# MCU_CTRL_MMR_MCU_CTRL_MMR_CFG0_04500000h register map
Vendor: Texas Instruments
Peripheral module from a debugger description file (folder am62D).
Registers are 32-bit, read-write, reset 0x0 unless marked. A register's access mark holds for its fields unless they carry their own. Offsets are as the file gives them; lines under a group give offsets from that group; [hi:lo] are bit positions; {n}, {i} and the like mark numbered series; 'fields as' and 'values as' point back to an identical list; <NAME> marks a mode.

## MCU_CTRL_MMR_CFG0 (part 1 of 3)
0x8070 MCU_CTRL_MMR_CFG0_MCU_GPIO_CLKSEL
  [1:0] MCU_GPIO_CLKSEL_CLK_SEL — MCU_GPIO clock selection. Must be set to MCU_SYSCLK0/4 whenever MCU_GPIO VBUS interface is activated. Other clock source may be selected as a clk_sel up clock for DeepSleep modes after MCU_GPIO is gated off through LPSC.Field values (others are reserved):2'b00 - MCU_SYSCLK0 / 82'b01 - LFSOSC_CLKOUT 2'b10 - CLK_32K2'b11 - CLK_12M_RC Reset Source: mod_por_rst_n
0x8080 MCU_CTRL_MMR_CFG0_MCU_MCAN0_CLKSEL
  [1:0] MCU_MCAN0_CLKSEL_CLK_SEL — Selects the clock source for MCAN0Field values (others are reserved):2'b00 - MCU_PLL0_HSDIV4_CLKOUT2'b01 - MCU_EXT_REFCLK02'b10 - HFOSC0_CLKOUT2'b11 - HFOSC0_CLKOUT Reset Source: mod_g_rst_n
0x8084 MCU_CTRL_MMR_CFG0_MCU_MCAN1_CLKSEL
  [1:0] MCU_MCAN1_CLKSEL_CLK_SEL — Selects the clock source for MCAN1Field values (others are reserved):2'b00 - MCU_PLL0_HSDIV4_CLKOUT2'b01 - MCU_EXT_REFCLK02'b10 - HFOSC0_CLKOUT2'b11 - HFOSC0_CLKOUT Reset Source: mod_g_rst_n
0x80A0 MCU_CTRL_MMR_CFG0_MCU_SPI0_CLKSEL
  [16] MCU_SPI0_CLKSEL_MSTR_LB_CLKSEL — Controller mode receive capture clock loopback selection 1'b0 - Internal clock loopback 1'b1 - Loopback from pad Reset Source: mod_g_rst_n
0x80A4 MCU_CTRL_MMR_CFG0_MCU_SPI1_CLKSEL
  [16] MCU_SPI1_CLKSEL_MSTR_LB_CLKSEL — Controller mode receive capture clock loopback selection 1'b0 - Internal clock loopback 1'b1 - Loopback from pad Reset Source: mod_g_rst_n
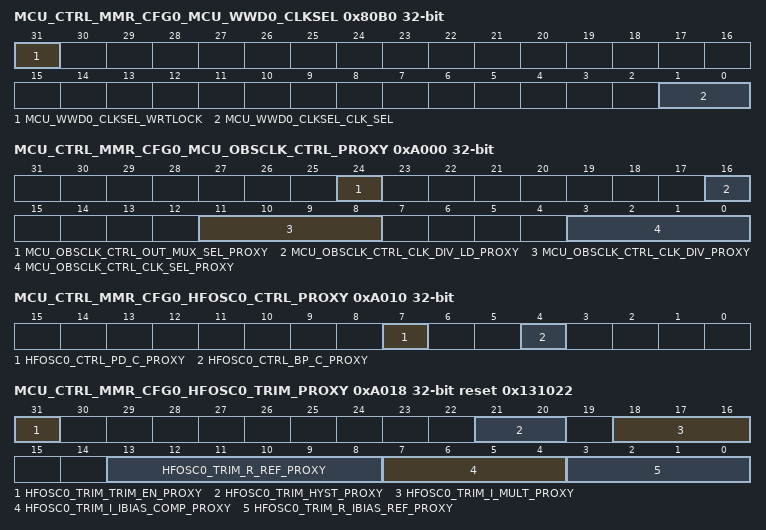
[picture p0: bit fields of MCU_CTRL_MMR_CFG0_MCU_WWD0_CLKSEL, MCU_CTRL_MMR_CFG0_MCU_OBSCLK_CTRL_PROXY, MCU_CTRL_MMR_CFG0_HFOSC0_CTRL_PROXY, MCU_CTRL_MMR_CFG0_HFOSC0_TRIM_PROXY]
0x80B0 MCU_CTRL_MMR_CFG0_MCU_WWD0_CLKSEL
  [31] MCU_WWD0_CLKSEL_WRTLOCK — When set, locks WWD0_CLKSEL from further writes until the next module reset. Reset Source: mod_g_rst_n
  [1:0] MCU_WWD0_CLKSEL_CLK_SEL — Windowed watchdog timer functional clock input select mux controlField values (others are reserved):2'b00 - HFOSC0_CLKOUT2'b01 - DEVICE_CLKOUT_32K2'b10 - CLK_12M_RC2'b11 - CLK_32K_RC Reset Source: mod_g_rst_n
0x9100 MCU_CTRL_MMR_CFG0_CLAIMREG_P2_R0_READONLY ro
  [31:0] CLAIMREG_P2_R0_READONLY — Claim bits for Partition 2 Reset Source: mod_g_rst_n
0x9104 MCU_CTRL_MMR_CFG0_CLAIMREG_P2_R1_READONLY ro
  [31:0] CLAIMREG_P2_R1_READONLY — Claim bits for Partition 2 Reset Source: mod_g_rst_n
0xA000 MCU_CTRL_MMR_CFG0_MCU_OBSCLK_CTRL_PROXY
  [24] MCU_OBSCLK_CTRL_OUT_MUX_SEL_PROXY — MCU_OBSCLK pin output mux selection.Note, HFOSC0_CLK is a direct output from the HFOSC0, distinct from HFOSC0_CLKOUT.Note, when HFOSC0_CLK is selected (1'b1) the MCU_OBSCLK_CTRL_clk_sel field must be programmed to 4'b0001. 1'b0 - The output of the MCU_OBSCLK output divider is output on the pin 1'b1 - HFOSC0_CLK is output on the pin Reset Source: mod_por_rst_n
  [16] MCU_OBSCLK_CTRL_CLK_DIV_LD_PROXY — Load the output divider valueWriting 1 to this bit will generate a load pulse to load the OBSCLK divider value. This bit can be cleared but must not be set in the same write cycle in which the clk_div value is changed. Reset Source: mod_por_rst_n
  [11:8] MCU_OBSCLK_CTRL_CLK_DIV_PROXY — MCU_OBSCLK pin clock selection output dividerOutput clock is divided by clk_div+1 Reset Source: mod_por_rst_n
  [3:0] MCU_OBSCLK_CTRL_CLK_SEL_PROXY — MCU_OBSCLK pin clock selectionField values (others are reserved):4'b0000 - CLK_12M_RC4'b0001 - '0'4'b0010 - MCU_PLL0_HSDIV0_CLKOUT4'b0011 - MCU_PLL0_HSDIV4_CLKOUT4'b0100 - MCU_PLLCTRL_OBSCLK4'b0101 - CLK_32K_RC4'b0110 - HFOSC0_CLKOUT4'b0111 - HFOSC0_CLKOUT_32K4'b1000 - MCU_SYSCLK04'b1001 - DEVICE_CLKOUT_32K Reset Source: mod_por_rst_n
0xA010 MCU_CTRL_MMR_CFG0_HFOSC0_CTRL_PROXY
  [7] HFOSC0_CTRL_PD_C_PROXY — Oscillator powerdown control. When set, oscillator is deactivated. Oscillator output is tristated if bp_c=0 Reset Source: mod_por_rst_n
  [4] HFOSC0_CTRL_BP_C_PROXY — Reserved - Must Write '0' Reset Source: mod_por_rst_n
0xA018 MCU_CTRL_MMR_CFG0_HFOSC0_TRIM_PROXY reset 0x131022
  [31] HFOSC0_TRIM_TRIM_EN_PROXY — Apply MMR values to OSC trim inputs instead of tie-offs Reset Source: mod_por_rst_n
  [21:20] HFOSC0_TRIM_HYST_PROXY — Sets comparator hysterisis Reset Source: mod_por_rst_n
  [18:16] HFOSC0_TRIM_I_MULT_PROXY — AGC AMP current multiplication gain Reset Source: mod_por_rst_n
  [13:8] HFOSC0_TRIM_R_REF_PROXY — Sets the AMP AGC bias current Reset Source: mod_por_rst_n
  [7:4] HFOSC0_TRIM_I_IBIAS_COMP_PROXY — Sets the COMP bias current Reset Source: mod_por_rst_n
  [3:0] HFOSC0_TRIM_R_IBIAS_REF_PROXY — Sets the base IBIAS reference Reset Source: mod_por_rst_n
0xA020 MCU_CTRL_MMR_CFG0_HFOSC0_STAT_PROXY ro
  [0] HFOSC0_STAT_DS_ON_WFI_STAT_PROXY — Allows MCU to monitor the DM attempting a Deep Sleep Reset Source: mod_g_rst_n
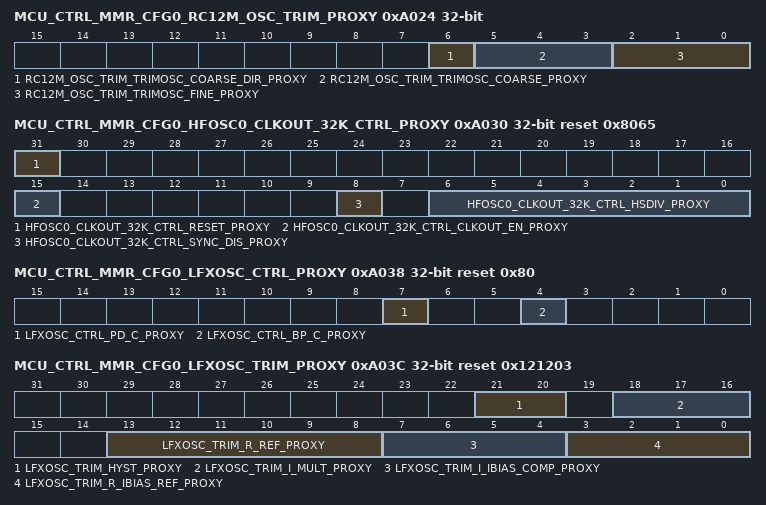
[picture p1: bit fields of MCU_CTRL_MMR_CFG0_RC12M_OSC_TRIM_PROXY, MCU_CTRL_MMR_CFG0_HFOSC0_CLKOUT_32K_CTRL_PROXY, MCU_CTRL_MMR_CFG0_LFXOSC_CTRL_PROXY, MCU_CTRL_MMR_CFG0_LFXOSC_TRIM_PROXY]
0xA024 MCU_CTRL_MMR_CFG0_RC12M_OSC_TRIM_PROXY
  [6] RC12M_OSC_TRIM_TRIMOSC_COARSE_DIR_PROXY — Coarse adjustment direction. If output is greater than 12.5 0 - Coarse adjustment decreases frequency 1 - Coarse adjustment increases frequency Reset Source: mod_por_rst_n
  [5:3] RC12M_OSC_TRIM_TRIMOSC_COARSE_PROXY — Coarse adjustment. Frequency is decreased or increased by 1.25 MHz per value based on the trimosc_coarse_dir value. Reset Source: mod_por_rst_n
  [2:0] RC12M_OSC_TRIM_TRIMOSC_FINE_PROXY — Fine adjustment. Decreases the frequency by 250 KHz per value. Reset Source: mod_por_rst_n
0xA030 MCU_CTRL_MMR_CFG0_HFOSC0_CLKOUT_32K_CTRL_PROXY reset 0x8065
  [31] HFOSC0_CLKOUT_32K_CTRL_RESET_PROXY — Asynchronous Divider Reset1 = Divider is Reset, HFOSC0_CLKOUT32K reset.0 = Divider out of reset, HFOSC0_CLKOUT_32K running. Reset Source: sys_por_rst_n
  [15] HFOSC0_CLKOUT_32K_CTRL_CLKOUT_EN_PROXY — HFOSC0_CLKOUT_32K activate: 0 = Synchronously Deactivate HFOSC0_CLKOUT_32KHz 1 = Synchronously Activate HFOSC0_CKLKOUT_32KHz Reset Source: sys_por_rst_n
  [8] HFOSC0_CLKOUT_32K_CTRL_SYNC_DIS_PROXY — HFOSC0_CLKOUT_32K Synchronize Deactivate 0 = Divider Updates are shadowed and take effect on counter reset. 1 = Divider Updates are immediate and hazardousDo not set this bit to 1'b1 during normal use. Reset Source: sys_por_rst_n
  [6:0] HFOSC0_CLKOUT_32K_CTRL_HSDIV_PROXY — HFOSC0_CLKOUT_32K divider:HFOSC0_CLKKOUT_32K Frequency = HFOSC0 Frequency / [8 * (hsdiv + 1)]Ex. HFOSC0 Frequency = 26MHz. hsdiv = 101 (Default)HFOSC0_CLKOUT_32K = 26MHz / (8 * (101+1)) = 26MHz / 816 = 31.9 KHz Reset Source: sys_por_rst_n
0xA038 MCU_CTRL_MMR_CFG0_LFXOSC_CTRL_PROXY reset 0x80
  [7] LFXOSC_CTRL_PD_C_PROXY — Oscillator powerdown control. When set, oscillator is deactivated. Oscillator output is tristated if bp_c=0 Reset Source: mod_por_rst_n
  [4] LFXOSC_CTRL_BP_C_PROXY — Oscillator bypass control. When set, oscillator is in bypass mode Reset Source: mod_por_rst_n
0xA03C MCU_CTRL_MMR_CFG0_LFXOSC_TRIM_PROXY reset 0x121203
  [21:20] LFXOSC_TRIM_HYST_PROXY — Sets comparator hysterisisField values (others are reserved):2'b00 - Hysteresis deactivated2'b01 - Type 1 hysteresis activated (Default)2'b10 - Type 2 hysteresis activated2'b11 - Both types 1 & 2 hysteresis activated Reset Source: mod_por_rst_n
  [18:16] LFXOSC_TRIM_I_MULT_PROXY — AGC AMP current multiplication gainField values (others are reserved):3'b000 - 3x AMP_AGC IBIAS3'b001 - 4x AMP_AGC IBIAS3'b010 - 5x AMP_AGC IBIAS (Default)3'b011 - 6x AMP_AGC IBIAS3'b100 - 7x AMP_AGC IBIAS3'b101 - 8x AMP_AGC IBIAS3'b110 - 9x AMP_AGC IBIAS3'b111 - 10x AMP_AGC IBIAS Reset Source: mod_por_rst_n
  [13:8] LFXOSC_TRIM_R_REF_PROXY — Sets the AMP AGC bias currentField values (others are reserved):6'b000000 - 0 K Ohm6'b000001 - 24 K Ohm6'b000010 - 48 K Ohm6'b000011 - 73 K Ohm6'b000100 - 97 K Ohm6'b000101 - 121 K Ohm6'b000110 - 145 K Ohm6'b000111 - 169 K Ohm6'b001000 - 193 K Ohm6'b001001 - 218 K Ohm6'b001010 - 242 K Ohm6'b001011 - 266 K Ohm6'b001100 - 290 K Ohm6'b001101 - 314 K Ohm6'b001110 - 338 K Ohm6'b001111 - 363 K Ohm6'b010000 - 387 K Ohm6'b010001 - 411 K Ohm6'b010010 - 435 K Ohm (Default)6'b010011 - 459 K Ohm6'b010100 - 483 K Ohm6'b010101 - 508 K Ohm6'b010110 - 532 K Ohm6'b010111 - 556 K Ohm6'b011000 - 580 K Ohm6'b011001 - 604 K Ohm6'b011010 - 628 K Ohm6'b011011 - 653 K Ohm6'b011100 - 677 K Ohm6'b011101 - 701 K Ohm6'b011110 - 725 K Ohm6'b011111 - 749 K Ohm6'b100000 - 773 K Ohm6'b100001 - 798 K Ohm6'b100010 - 822 K Ohm6'b100011 - 846 K Ohm6'b100100 - 870 K Ohm6'b100101 - 894 K Ohm6'b100110 - 918 K Ohm6'b100111 - 943 K Ohm6'b101000 - 967 K Ohm6'b101001 - 991 K Ohm6'b101010 - 1015 K Ohm6'b101011 - 1039 K Ohm6'b101100 - 1063 K Ohm6'b101101 - 1088 K Ohm6'b101110 - 1112 K Ohm6'b101111 - 1136 K Ohm6'b110000 - 1160 K Ohm6'b110001 - 1184 K Ohm6'b110010 - 1208 K Ohm6'b110011 - 1233 K Ohm6'b110100 - 1257 K Ohm6'b110101 - 1281 K Ohm6'b110110 - 1305 K Ohm6'b110111 - 1329 K Ohm6'b111000 - 1353 K Ohm6'b111001 - 1378 K Ohm6'b111010 - 1402 K Ohm6'b111011 - 1426 K Ohm6'b111100 - 1450 K Ohm6'b111101 - 1474 K Ohm6'b111110 - 1498 K Ohm6'b111111 - 1523 K Ohm Reset Source: mod_por_rst_n
  [7:4] LFXOSC_TRIM_I_IBIAS_COMP_PROXY — Sets the COMP bias currentField values (others are reserved):4'b0000 - Base IBIAS ref x24'b0001 - Base IBIAS ref x34'b0010 - Base IBIAS ref x44'b0011 - Base IBIAS ref x54'b0100 - Base IBIAS ref x64'b0101 - Base IBIAS ref x74'b0110 - Base IBIAS ref x84'b0111 - Base IBIAS ref x94'b1000 - Base IBIAS ref x104'b1001 - Base IBIAS ref x114'b1010 - Base IBIAS ref x124'b1011 - Base IBIAS ref x134'b1100 - Base IBIAS ref x144'b1101 - Base IBIAS ref x154'b1110 - Base IBIAS ref x164'b1111 - Base IBIAS ref x17 Reset Source: mod_por_rst_n
  [3:0] LFXOSC_TRIM_R_IBIAS_REF_PROXY — Sets the base IBIAS referenceField values (others are reserved):4'b0000 - 512 K Ohm4'b0001 - 576 K Ohm4'b0010 - 640 K Ohm4'b0011 - 704 K Ohm (Default)4'b0100 - 768 K Ohm4'b0101 - 832 K Ohm4'b0110 - 896 K Ohm4'b0111 - 960 K Ohm4'b1000 - 1024 K Ohm4'b1001 - 1088 K Ohm4'b1010 - 1152 K Ohm4'b1011 - 1216 K Ohm4'b1100 - 1280 K Ohm4'b1101 - 1344 K Ohm4'b1110 - 1408 K Ohm4'b1111 - 1472 K Ohm Reset Source: mod_por_rst_n
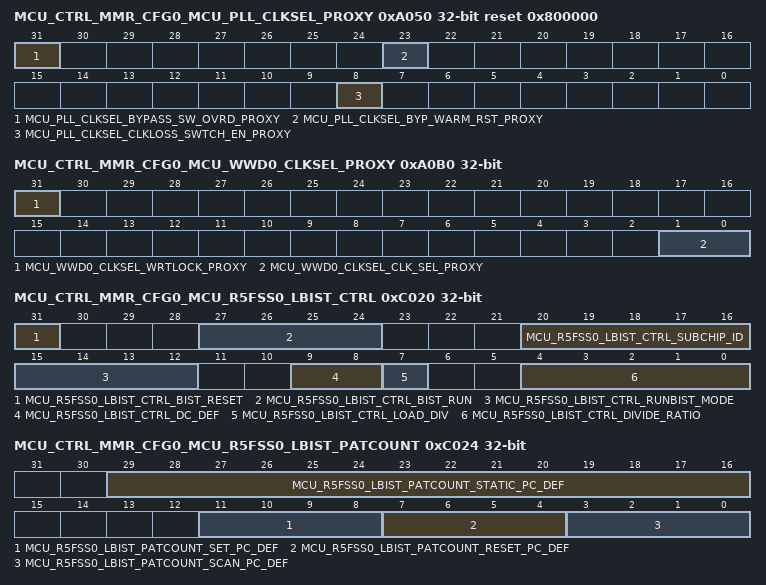
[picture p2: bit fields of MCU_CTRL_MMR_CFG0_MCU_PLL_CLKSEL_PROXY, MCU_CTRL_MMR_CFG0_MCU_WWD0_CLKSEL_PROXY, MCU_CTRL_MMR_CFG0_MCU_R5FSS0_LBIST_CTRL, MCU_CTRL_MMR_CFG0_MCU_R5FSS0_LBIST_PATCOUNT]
0xA050 MCU_CTRL_MMR_CFG0_MCU_PLL_CLKSEL_PROXY reset 0x800000
  [31] MCU_PLL_CLKSEL_BYPASS_SW_OVRD_PROXY — PLL Bypass warm reset software overrideWhen set, activates software control of exit from bypass mode on a mcu_reset_z for MCU PLL[2:0]. This bit must not be set until after the corresponding byp_warm_rst bit has been cleared or the PLL will immediately enter bypass mode. Reset Source: sys_por_rst_n
  [23] MCU_PLL_CLKSEL_BYP_WARM_RST_PROXY — PLL bypass mode after warm reset.This bit is only valid when bypass_sw_ovrd is set to 1'b1 to activate bypass software override.This bit is set (1'b1) when an MCU warm reset occurs and will keep MCU PLL[2:0] in bypass mode after reset exit until cleared by software. 1'b0 = Exit bypass mode (based on MCU PLL[2:0]_CTRL_bypass_en bit value) 1'b1 = Maintain bypass mode. Reset Source: mcu_chip1_rst_n
  [8] MCU_PLL_CLKSEL_CLKLOSS_SWTCH_EN_PROXY — When set, activates automatic switching of MCU PLL[2:0] clock source to CLK_12M_RC if HFOSC0 clock loss is detected Reset Source: mod_por_rst_n
0xA058 MCU_CTRL_MMR_CFG0_DEVICE_CLKOUT_32K_CTRL_PROXY
  [1:0] DEVICE_CLKOUT_32K_CTRL_CLK_32K_RC_SEL_PROXY — Selects the source of the device level 32KHz ClockField values (others are reserved):2'b00 - CLK_32K_RC2'b01 - HFOSC0_CLKOUT_32K2'b10 - Reserved - (implementation: CLK_32K_RC)2'b11 - LFOSC0_CLKOUT Reset Source: mod_g_rst_n
{0xA060+4i} MCU_CTRL_MMR_CFG0_MCU_TIMER{i}_CLKSEL_PROXY (i=0..3)
  [2:0] MCU_TIMER{i}_CLKSEL_CLK_SEL_PROXY — Timer functional clock input select mux control (Reserved values default to HFOSC0_CLK)Field values (others are reserved):3'b000 - HFOSC0_CLKOUT3'b001 - MCU_SYSCLK0 / 23'b010 - CLK_12M_RC3'b011 - MCU_PLL0_HSDIV5_CLKOUT3'b100 - MCU_EXT_REFCLK03'b101 - DEVICE_CLKOUT_32K3'b110 - CPSW_GENF03'b111 - CLK_32K_RC Reset Source: sys_por_rst_n
0xA070 MCU_CTRL_MMR_CFG0_MCU_GPIO_CLKSEL_PROXY
  [1:0] MCU_GPIO_CLKSEL_CLK_SEL_PROXY — MCU_GPIO clock selection. Must be set to MCU_SYSCLK0/4 whenever MCU_GPIO VBUS interface is activated. Other clock source may be selected as a clk_sel up clock for DeepSleep modes after MCU_GPIO is gated off through LPSC.Field values (others are reserved):2'b00 - MCU_SYSCLK0 / 82'b01 - LFSOSC_CLKOUT 2'b10 - CLK_32K2'b11 - CLK_12M_RC Reset Source: mod_por_rst_n
0xA080 MCU_CTRL_MMR_CFG0_MCU_MCAN0_CLKSEL_PROXY
  [1:0] MCU_MCAN0_CLKSEL_CLK_SEL_PROXY — Selects the clock source for MCAN0Field values (others are reserved):2'b00 - MCU_PLL0_HSDIV4_CLKOUT2'b01 - MCU_EXT_REFCLK02'b10 - HFOSC0_CLKOUT2'b11 - HFOSC0_CLKOUT Reset Source: mod_g_rst_n
0xA084 MCU_CTRL_MMR_CFG0_MCU_MCAN1_CLKSEL_PROXY
  [1:0] MCU_MCAN1_CLKSEL_CLK_SEL_PROXY — Selects the clock source for MCAN1Field values (others are reserved):2'b00 - MCU_PLL0_HSDIV4_CLKOUT2'b01 - MCU_EXT_REFCLK02'b10 - HFOSC0_CLKOUT2'b11 - HFOSC0_CLKOUT Reset Source: mod_g_rst_n
0xA0A0 MCU_CTRL_MMR_CFG0_MCU_SPI0_CLKSEL_PROXY
  [16] MCU_SPI0_CLKSEL_MSTR_LB_CLKSEL_PROXY — Controller mode receive capture clock loopback selection 1'b0 - Internal clock loopback 1'b1 - Loopback from pad Reset Source: mod_g_rst_n
0xA0A4 MCU_CTRL_MMR_CFG0_MCU_SPI1_CLKSEL_PROXY
  [16] MCU_SPI1_CLKSEL_MSTR_LB_CLKSEL_PROXY — Controller mode receive capture clock loopback selection 1'b0 - Internal clock loopback 1'b1 - Loopback from pad Reset Source: mod_g_rst_n
0xA0B0 MCU_CTRL_MMR_CFG0_MCU_WWD0_CLKSEL_PROXY
  [31] MCU_WWD0_CLKSEL_WRTLOCK_PROXY — When set, locks WWD0_CLKSEL from further writes until the next module reset. Reset Source: mod_g_rst_n
  [1:0] MCU_WWD0_CLKSEL_CLK_SEL_PROXY — Windowed watchdog timer functional clock input select mux controlField values (others are reserved):2'b00 - HFOSC0_CLKOUT2'b01 - DEVICE_CLKOUT_32K2'b10 - CLK_12M_RC2'b11 - CLK_32K_RC Reset Source: mod_g_rst_n
0xB100 MCU_CTRL_MMR_CFG0_CLAIMREG_P2_R0
  [31:0] CLAIMREG_P2_R0 — Claim bits for Partition 2 Reset Source: mod_g_rst_n
0xB104 MCU_CTRL_MMR_CFG0_CLAIMREG_P2_R1
  [31:0] CLAIMREG_P2_R1 — Claim bits for Partition 2 Reset Source: mod_g_rst_n
0xC020 MCU_CTRL_MMR_CFG0_MCU_R5FSS0_LBIST_CTRL
  [31] MCU_R5FSS0_LBIST_CTRL_BIST_RESET — This bitfield is not used. Reset Source: mod_g_rst_n
  [27:24] MCU_R5FSS0_LBIST_CTRL_BIST_RUN — This bitfield is not used. Reset Source: mod_g_rst_n
  [20:16] MCU_R5FSS0_LBIST_CTRL_SUBCHIP_ID — Specifies which sub-chip is to be tested Reset Source: mod_g_rst_n
  [15:12] MCU_R5FSS0_LBIST_CTRL_RUNBIST_MODE — Runbist mode activate if all bits are 1 Reset Source: mod_g_rst_n
  [9:8] MCU_R5FSS0_LBIST_CTRL_DC_DEF — Clock delay after scan_activate switching Reset Source: mod_g_rst_n
  [7] MCU_R5FSS0_LBIST_CTRL_LOAD_DIV — Loads LBIST clock divide ratio on transition from 0 to 1 Reset Source: mod_g_rst_n
  [4:0] MCU_R5FSS0_LBIST_CTRL_DIVIDE_RATIO — LBIST clock divide ratio Reset Source: mod_g_rst_n
0xC024 MCU_CTRL_MMR_CFG0_MCU_R5FSS0_LBIST_PATCOUNT
  [29:16] MCU_R5FSS0_LBIST_PATCOUNT_STATIC_PC_DEF — Number of stuck-at patterns to run Reset Source: mod_g_rst_n
  [11:8] MCU_R5FSS0_LBIST_PATCOUNT_SET_PC_DEF — Number of set patterns to run Reset Source: mod_g_rst_n
  [7:4] MCU_R5FSS0_LBIST_PATCOUNT_RESET_PC_DEF — Number of reset patterns to run Reset Source: mod_g_rst_n
  [3:0] MCU_R5FSS0_LBIST_PATCOUNT_SCAN_PC_DEF — Number of chain test patterns to run Reset Source: mod_g_rst_n
0xC028 MCU_CTRL_MMR_CFG0_MCU_R5FSS0_LBIST_SEED0
  [31:0] MCU_R5FSS0_LBIST_SEED0_PRPG_DEF — Initial seed for PRPG (bits 31:0) Reset Source: mod_g_rst_n
0xC02C MCU_CTRL_MMR_CFG0_MCU_R5FSS0_LBIST_SEED1
  [20:0] MCU_R5FSS0_LBIST_SEED1_PRPG_DEF — Initial seed for PRPG (bits 52:32) Reset Source: mod_g_rst_n
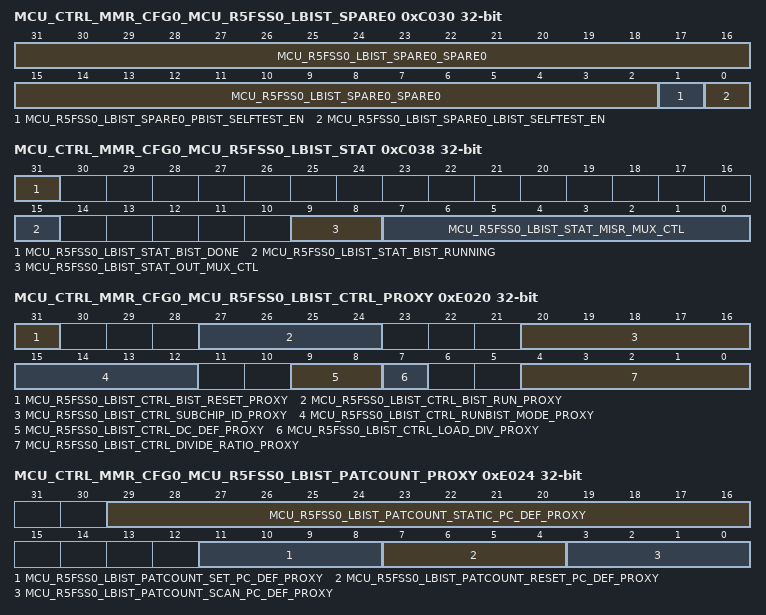
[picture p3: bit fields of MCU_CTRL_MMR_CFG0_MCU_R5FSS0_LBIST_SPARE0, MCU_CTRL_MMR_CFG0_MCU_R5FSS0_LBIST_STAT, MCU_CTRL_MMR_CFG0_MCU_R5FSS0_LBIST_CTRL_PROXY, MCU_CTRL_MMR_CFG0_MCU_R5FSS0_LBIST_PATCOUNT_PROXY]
0xC030 MCU_CTRL_MMR_CFG0_MCU_R5FSS0_LBIST_SPARE0
  [31:2] MCU_R5FSS0_LBIST_SPARE0_SPARE0 — LBIST spare bits Reset Source: mod_g_rst_n
  [1] MCU_R5FSS0_LBIST_SPARE0_PBIST_SELFTEST_EN — PBIST isolation control Reset Source: mod_g_rst_n
  [0] MCU_R5FSS0_LBIST_SPARE0_LBIST_SELFTEST_EN — LBIST isolation control Reset Source: mod_g_rst_n
0xC034 MCU_CTRL_MMR_CFG0_MCU_R5FSS0_LBIST_SPARE1
  [31:0] MCU_R5FSS0_LBIST_SPARE1_SPARE1 — LBIST spare bits Reset Source: mod_g_rst_n
0xC038 MCU_CTRL_MMR_CFG0_MCU_R5FSS0_LBIST_STAT access per field
  [31] MCU_R5FSS0_LBIST_STAT_BIST_DONE ro — LBIST is done Reset Source: mod_g_rst_n
  [15] MCU_R5FSS0_LBIST_STAT_BIST_RUNNING ro — LBIST is running Reset Source: mod_g_rst_n
  [9:8] MCU_R5FSS0_LBIST_STAT_OUT_MUX_CTL rw — Selects source of LBIST output 00 - LBIST IP PID value 01 - LBIST CTRL ID value 1x - MISR value Reset Source: mod_g_rst_n
  [7:0] MCU_R5FSS0_LBIST_STAT_MISR_MUX_CTL rw — Selects block of 32 MISR bits to read. A value of 0 selects a compacted 32-bit version of the full MISR. A value of 1-32 select a 32-bit segment of the MISR. Reset Source: mod_g_rst_n
0xC03C MCU_CTRL_MMR_CFG0_MCU_R5FSS0_LBIST_MISR ro
  [31:0] MCU_R5FSS0_LBIST_MISR_MISR_RESULT — 32-bits of MISR value selected by misr_mux_ctl Reset Source: mod_g_rst_n
0xD100 MCU_CTRL_MMR_CFG0_CLAIMREG_P3_R0_READONLY ro
  [31:0] CLAIMREG_P3_R0_READONLY — Claim bits for Partition 3 Reset Source: mod_g_rst_n
0xE020 MCU_CTRL_MMR_CFG0_MCU_R5FSS0_LBIST_CTRL_PROXY
  [31] MCU_R5FSS0_LBIST_CTRL_BIST_RESET_PROXY — This bitfield is not used. Reset Source: mod_g_rst_n
  [27:24] MCU_R5FSS0_LBIST_CTRL_BIST_RUN_PROXY — This bitfield is not used. Reset Source: mod_g_rst_n
  [20:16] MCU_R5FSS0_LBIST_CTRL_SUBCHIP_ID_PROXY — Specifies which sub-chip is to be tested Reset Source: mod_g_rst_n
  [15:12] MCU_R5FSS0_LBIST_CTRL_RUNBIST_MODE_PROXY — Runbist mode activate if all bits are 1 Reset Source: mod_g_rst_n
  [9:8] MCU_R5FSS0_LBIST_CTRL_DC_DEF_PROXY — Clock delay after scan_activate switching Reset Source: mod_g_rst_n
  [7] MCU_R5FSS0_LBIST_CTRL_LOAD_DIV_PROXY — Loads LBIST clock divide ratio on transition from 0 to 1 Reset Source: mod_g_rst_n
  [4:0] MCU_R5FSS0_LBIST_CTRL_DIVIDE_RATIO_PROXY — LBIST clock divide ratio Reset Source: mod_g_rst_n
0xE024 MCU_CTRL_MMR_CFG0_MCU_R5FSS0_LBIST_PATCOUNT_PROXY
  [29:16] MCU_R5FSS0_LBIST_PATCOUNT_STATIC_PC_DEF_PROXY — Number of stuck-at patterns to run Reset Source: mod_g_rst_n
  [11:8] MCU_R5FSS0_LBIST_PATCOUNT_SET_PC_DEF_PROXY — Number of set patterns to run Reset Source: mod_g_rst_n
  [7:4] MCU_R5FSS0_LBIST_PATCOUNT_RESET_PC_DEF_PROXY — Number of reset patterns to run Reset Source: mod_g_rst_n
  [3:0] MCU_R5FSS0_LBIST_PATCOUNT_SCAN_PC_DEF_PROXY — Number of chain test patterns to run Reset Source: mod_g_rst_n
0xE028 MCU_CTRL_MMR_CFG0_MCU_R5FSS0_LBIST_SEED0_PROXY
  [31:0] MCU_R5FSS0_LBIST_SEED0_PRPG_DEF_PROXY — Initial seed for PRPG (bits 31:0) Reset Source: mod_g_rst_n
0xE02C MCU_CTRL_MMR_CFG0_MCU_R5FSS0_LBIST_SEED1_PROXY
  [20:0] MCU_R5FSS0_LBIST_SEED1_PRPG_DEF_PROXY — Initial seed for PRPG (bits 52:32) Reset Source: mod_g_rst_n
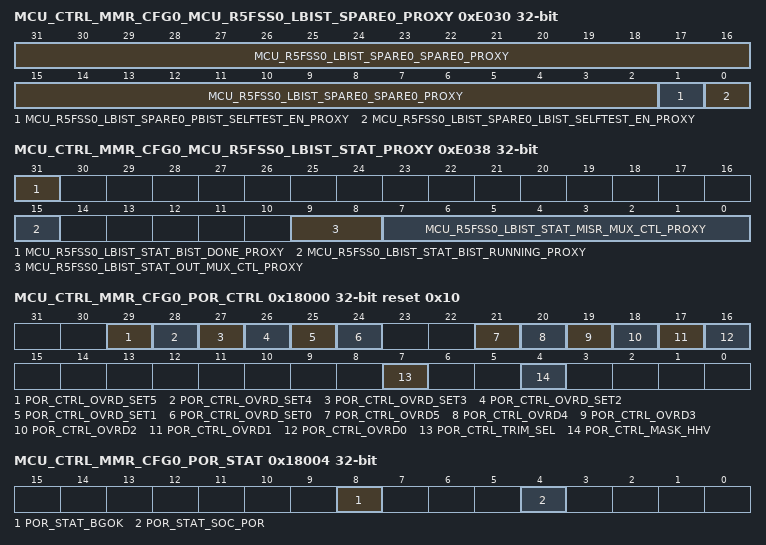
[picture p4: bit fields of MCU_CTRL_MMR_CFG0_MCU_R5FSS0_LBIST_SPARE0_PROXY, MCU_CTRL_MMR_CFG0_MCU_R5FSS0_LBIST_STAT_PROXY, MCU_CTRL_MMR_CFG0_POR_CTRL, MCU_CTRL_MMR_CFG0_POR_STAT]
0xE030 MCU_CTRL_MMR_CFG0_MCU_R5FSS0_LBIST_SPARE0_PROXY
  [31:2] MCU_R5FSS0_LBIST_SPARE0_SPARE0_PROXY — LBIST spare bits Reset Source: mod_g_rst_n
  [1] MCU_R5FSS0_LBIST_SPARE0_PBIST_SELFTEST_EN_PROXY — PBIST isolation control Reset Source: mod_g_rst_n
  [0] MCU_R5FSS0_LBIST_SPARE0_LBIST_SELFTEST_EN_PROXY — LBIST isolation control Reset Source: mod_g_rst_n
0xE034 MCU_CTRL_MMR_CFG0_MCU_R5FSS0_LBIST_SPARE1_PROXY
  [31:0] MCU_R5FSS0_LBIST_SPARE1_SPARE1_PROXY — LBIST spare bits Reset Source: mod_g_rst_n
0xE038 MCU_CTRL_MMR_CFG0_MCU_R5FSS0_LBIST_STAT_PROXY access per field
  [31] MCU_R5FSS0_LBIST_STAT_BIST_DONE_PROXY ro — LBIST is done Reset Source: mod_g_rst_n
  [15] MCU_R5FSS0_LBIST_STAT_BIST_RUNNING_PROXY ro — LBIST is running Reset Source: mod_g_rst_n
  [9:8] MCU_R5FSS0_LBIST_STAT_OUT_MUX_CTL_PROXY rw — Selects source of LBIST output 00 - LBIST IP PID value 01 - LBIST CTRL ID value 1x - MISR value Reset Source: mod_g_rst_n
  [7:0] MCU_R5FSS0_LBIST_STAT_MISR_MUX_CTL_PROXY rw — Selects block of 32 MISR bits to read. A value of 0 selects a compacted 32-bit version of the full MISR. A value of 1-32 select a 32-bit segment of the MISR. Reset Source: mod_g_rst_n
0xE03C MCU_CTRL_MMR_CFG0_MCU_R5FSS0_LBIST_MISR_PROXY ro
  [31:0] MCU_R5FSS0_LBIST_MISR_MISR_RESULT_PROXY — 32-bits of MISR value selected by misr_mux_ctl Reset Source: mod_g_rst_n
0xF100 MCU_CTRL_MMR_CFG0_CLAIMREG_P3_R0
  [31:0] CLAIMREG_P3_R0 — Claim bits for Partition 3 Reset Source: mod_g_rst_n
{0x11100+4i} MCU_CTRL_MMR_CFG0_CLAIMREG_P4_R{i}_READONLY ro (i=0..19)
  [31:0] CLAIMREG_P4_R{i}_READONLY — Claim bits for Partition 4 Reset Source: mod_g_rst_n
{0x13100+4i} MCU_CTRL_MMR_CFG0_CLAIMREG_P4_R{i} (i=0..19)
  [31:0] CLAIMREG_P4_R{i} — Claim bits for Partition 4 Reset Source: mod_g_rst_n
0x18000 MCU_CTRL_MMR_CFG0_POR_CTRL reset 0x10
  [29] POR_CTRL_OVRD_SET5 — Reserved override set Reset Source: mod_por_rst_n
  [28] POR_CTRL_OVRD_SET4 — POKLVB override set Reset Source: mod_por_rst_n
  [27] POR_CTRL_OVRD_SET3 — POKLVA override set Reset Source: mod_por_rst_n
  [26] POR_CTRL_OVRD_SET2 — POKHV override set Reset Source: mod_por_rst_n
  [25] POR_CTRL_OVRD_SET1 — BGOK override set Reset Source: mod_por_rst_n
  [24] POR_CTRL_OVRD_SET0 — PORHV override set Reset Source: mod_por_rst_n
  [21] POR_CTRL_OVRD5 — Reserved override activate Reset Source: mod_por_rst_n
  [20] POR_CTRL_OVRD4 — POKLVB override activate Reset Source: mod_por_rst_n
  [19] POR_CTRL_OVRD3 — POKLVA override activate Reset Source: mod_por_rst_n
  [18] POR_CTRL_OVRD2 — POKHV override activate Reset Source: mod_por_rst_n
  [17] POR_CTRL_OVRD1 — BGOK override activate Reset Source: mod_por_rst_n
  [16] POR_CTRL_OVRD0 — PORHV override activate Reset Source: mod_por_rst_n
  [7] POR_CTRL_TRIM_SEL — POR Trim Select 0 - Trim selections for Bandgap and POKs come from HHV defaults 1 - Trim selections for Bandgap and POKs come from POR_BANDGAP_CTRL and POR_POKxxx_CTRL registers Reset Source: mod_por_rst_n
  [4] POR_CTRL_MASK_HHV — Mask HHV/SOC_PORz outputs when applying new trim values Reset Source: mod_por_rst_n
0x18004 MCU_CTRL_MMR_CFG0_POR_STAT ro
  [8] POR_STAT_BGOK — Bandgap OK status Reset Source: mod_por_rst_n
  [4] POR_STAT_SOC_POR — POR module status 0 - Module is in functional mode 1 - Module is in reset mode Reset Source: mod_por_rst_n
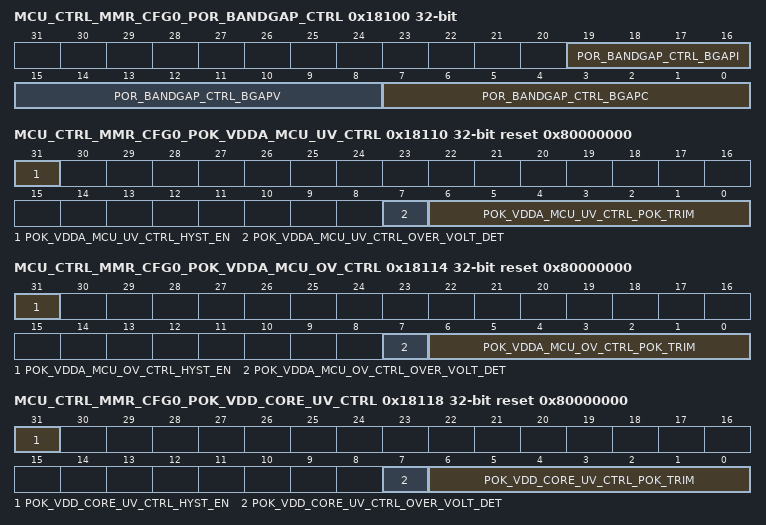
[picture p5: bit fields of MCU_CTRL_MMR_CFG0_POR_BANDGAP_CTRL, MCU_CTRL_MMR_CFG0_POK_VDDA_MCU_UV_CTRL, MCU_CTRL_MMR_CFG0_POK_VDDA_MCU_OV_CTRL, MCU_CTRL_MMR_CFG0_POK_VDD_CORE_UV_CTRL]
0x18100 MCU_CTRL_MMR_CFG0_POR_BANDGAP_CTRL
  [19:16] POR_BANDGAP_CTRL_BGAPI — Bandgap output current trim bits Reset Source: mod_por_rst_n
  [15:8] POR_BANDGAP_CTRL_BGAPV — Bandgap output voltage magnitude trim bits Reset Source: mod_por_rst_n
  [7:0] POR_BANDGAP_CTRL_BGAPC — Bandgap slope trim bits. Bit7 is used to calculate the offset Reset Source: mod_por_rst_n
0x18110 MCU_CTRL_MMR_CFG0_POK_VDDA_MCU_UV_CTRL reset 0x80000000
  [31] POK_VDDA_MCU_UV_CTRL_HYST_EN — Activate POK hysteresis Reset Source: mod_por_rst_n
  [7] POK_VDDA_MCU_UV_CTRL_OVER_VOLT_DET — Over / under voltage detection mode 0 - Under voltage detection 1 - Over voltage detection Reset Source: mod_por_rst_n
  [6:0] POK_VDDA_MCU_UV_CTRL_POK_TRIM — POK Trim Bits Reset Source: mod_por_rst_n
0x18114 MCU_CTRL_MMR_CFG0_POK_VDDA_MCU_OV_CTRL reset 0x80000000
  [31] POK_VDDA_MCU_OV_CTRL_HYST_EN — Activate POK hysteresis Reset Source: mod_por_rst_n
  [7] POK_VDDA_MCU_OV_CTRL_OVER_VOLT_DET — Over / under voltage detection mode 0 - Under voltage detection 1 - Over voltage detection Reset Source: mod_por_rst_n
  [6:0] POK_VDDA_MCU_OV_CTRL_POK_TRIM — POK Trim Bits Reset Source: mod_por_rst_n
0x18118 MCU_CTRL_MMR_CFG0_POK_VDD_CORE_UV_CTRL reset 0x80000000
  [31] POK_VDD_CORE_UV_CTRL_HYST_EN — Activate POK hysteresis Reset Source: mod_por_rst_n
  [7] POK_VDD_CORE_UV_CTRL_OVER_VOLT_DET — Over / under voltage detection mode 0 - Under voltage detection 1 - Over voltage detection Reset Source: mod_por_rst_n
  [6:0] POK_VDD_CORE_UV_CTRL_POK_TRIM — POK Trim Bits Reset Source: mod_por_rst_n
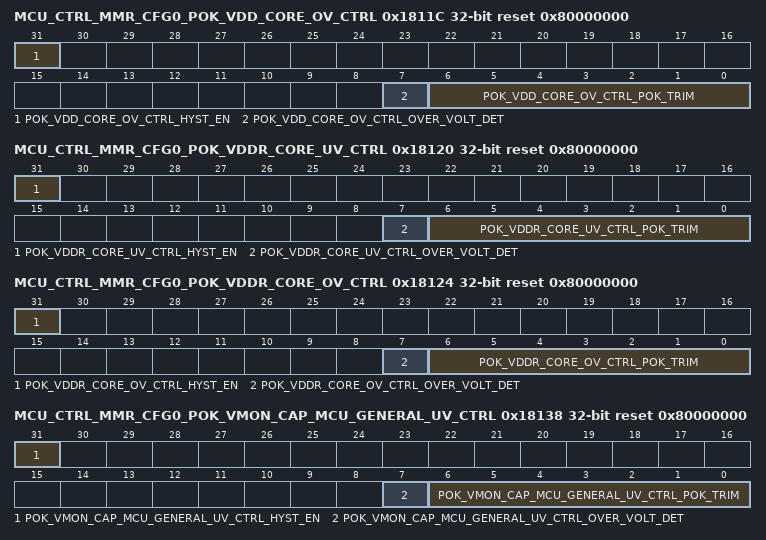
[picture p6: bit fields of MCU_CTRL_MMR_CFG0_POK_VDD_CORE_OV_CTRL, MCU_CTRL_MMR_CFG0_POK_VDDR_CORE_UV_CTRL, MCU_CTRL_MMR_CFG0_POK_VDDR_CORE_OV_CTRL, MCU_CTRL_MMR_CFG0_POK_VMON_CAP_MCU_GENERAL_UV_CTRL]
0x1811C MCU_CTRL_MMR_CFG0_POK_VDD_CORE_OV_CTRL reset 0x80000000
  [31] POK_VDD_CORE_OV_CTRL_HYST_EN — Activate POK hysteresis Reset Source: mod_por_rst_n
  [7] POK_VDD_CORE_OV_CTRL_OVER_VOLT_DET — Over / under voltage detection mode 0 - Under voltage detection 1 - Over voltage detection Reset Source: mod_por_rst_n
  [6:0] POK_VDD_CORE_OV_CTRL_POK_TRIM — POK Trim Bits Reset Source: mod_por_rst_n
0x18120 MCU_CTRL_MMR_CFG0_POK_VDDR_CORE_UV_CTRL reset 0x80000000
  [31] POK_VDDR_CORE_UV_CTRL_HYST_EN — Activate POK hysteresis Reset Source: mod_por_rst_n
  [7] POK_VDDR_CORE_UV_CTRL_OVER_VOLT_DET — Over / under voltage detection mode 0 - Under voltage detection 1 - Over voltage detection Reset Source: mod_por_rst_n
  [6:0] POK_VDDR_CORE_UV_CTRL_POK_TRIM — POK Trim Bits Reset Source: mod_por_rst_n
0x18124 MCU_CTRL_MMR_CFG0_POK_VDDR_CORE_OV_CTRL reset 0x80000000
  [31] POK_VDDR_CORE_OV_CTRL_HYST_EN — Activate POK hysteresis Reset Source: mod_por_rst_n
  [7] POK_VDDR_CORE_OV_CTRL_OVER_VOLT_DET — Over / under voltage detection mode 0 - Under voltage detection 1 - Over voltage detection Reset Source: mod_por_rst_n
  [6:0] POK_VDDR_CORE_OV_CTRL_POK_TRIM — POK Trim Bits Reset Source: mod_por_rst_n
0x18138 MCU_CTRL_MMR_CFG0_POK_VMON_CAP_MCU_GENERAL_UV_CTRL reset 0x80000000
  [31] POK_VMON_CAP_MCU_GENERAL_UV_CTRL_HYST_EN — Activate POK hysteresis Reset Source: mod_por_rst_n
  [7] POK_VMON_CAP_MCU_GENERAL_UV_CTRL_OVER_VOLT_DET — Over / under voltage detection mode 0 - Under voltage detection 1 - Over voltage detection Reset Source: mod_por_rst_n
  [6:0] POK_VMON_CAP_MCU_GENERAL_UV_CTRL_POK_TRIM — POK Trim Bits Reset Source: mod_por_rst_n
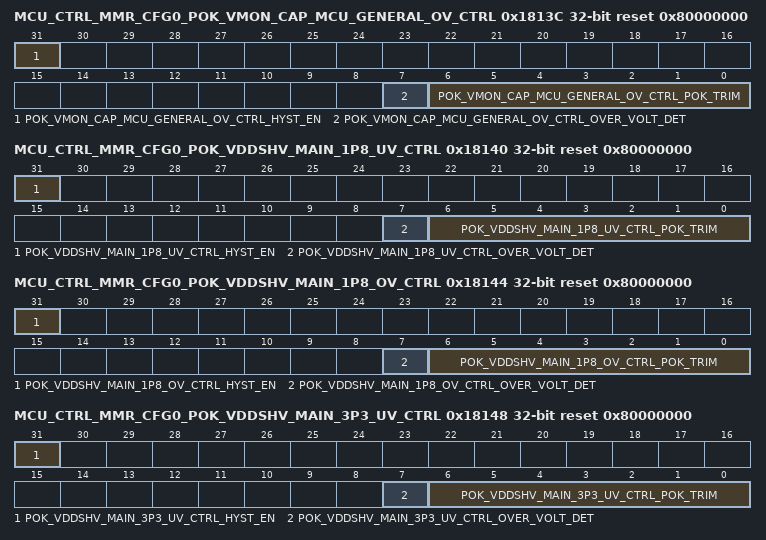
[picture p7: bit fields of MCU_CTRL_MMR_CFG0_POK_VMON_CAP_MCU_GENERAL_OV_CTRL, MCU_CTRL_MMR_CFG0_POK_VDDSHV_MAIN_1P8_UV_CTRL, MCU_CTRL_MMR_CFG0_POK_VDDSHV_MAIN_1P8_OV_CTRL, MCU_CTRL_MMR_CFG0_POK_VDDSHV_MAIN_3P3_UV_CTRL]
0x1813C MCU_CTRL_MMR_CFG0_POK_VMON_CAP_MCU_GENERAL_OV_CTRL reset 0x80000000
  [31] POK_VMON_CAP_MCU_GENERAL_OV_CTRL_HYST_EN — Activate POK hysteresis Reset Source: mod_por_rst_n
  [7] POK_VMON_CAP_MCU_GENERAL_OV_CTRL_OVER_VOLT_DET — Over / under voltage detection mode 0 - Under voltage detection 1 - Over voltage detection Reset Source: mod_por_rst_n
  [6:0] POK_VMON_CAP_MCU_GENERAL_OV_CTRL_POK_TRIM — POK Trim Bits Reset Source: mod_por_rst_n
0x18140 MCU_CTRL_MMR_CFG0_POK_VDDSHV_MAIN_1P8_UV_CTRL reset 0x80000000
  [31] POK_VDDSHV_MAIN_1P8_UV_CTRL_HYST_EN — Activate POK hysteresis Reset Source: mod_por_rst_n
  [7] POK_VDDSHV_MAIN_1P8_UV_CTRL_OVER_VOLT_DET — Over / under voltage detection mode 0 - Under voltage detection 1 - Over voltage detection Reset Source: mod_por_rst_n
  [6:0] POK_VDDSHV_MAIN_1P8_UV_CTRL_POK_TRIM — POK Trim Bits Reset Source: mod_por_rst_n
0x18144 MCU_CTRL_MMR_CFG0_POK_VDDSHV_MAIN_1P8_OV_CTRL reset 0x80000000
  [31] POK_VDDSHV_MAIN_1P8_OV_CTRL_HYST_EN — Activate POK hysteresis Reset Source: mod_por_rst_n
  [7] POK_VDDSHV_MAIN_1P8_OV_CTRL_OVER_VOLT_DET — Over / under voltage detection mode 0 - Under voltage detection 1 - Over voltage detection Reset Source: mod_por_rst_n
  [6:0] POK_VDDSHV_MAIN_1P8_OV_CTRL_POK_TRIM — POK Trim Bits Reset Source: mod_por_rst_n
0x18148 MCU_CTRL_MMR_CFG0_POK_VDDSHV_MAIN_3P3_UV_CTRL reset 0x80000000
  [31] POK_VDDSHV_MAIN_3P3_UV_CTRL_HYST_EN — Activate POK hysteresis Reset Source: mod_por_rst_n
  [7] POK_VDDSHV_MAIN_3P3_UV_CTRL_OVER_VOLT_DET — Over / under voltage detection mode 0 - Under voltage detection 1 - Over voltage detection Reset Source: mod_por_rst_n
  [6:0] POK_VDDSHV_MAIN_3P3_UV_CTRL_POK_TRIM — POK Trim Bits Reset Source: mod_por_rst_n
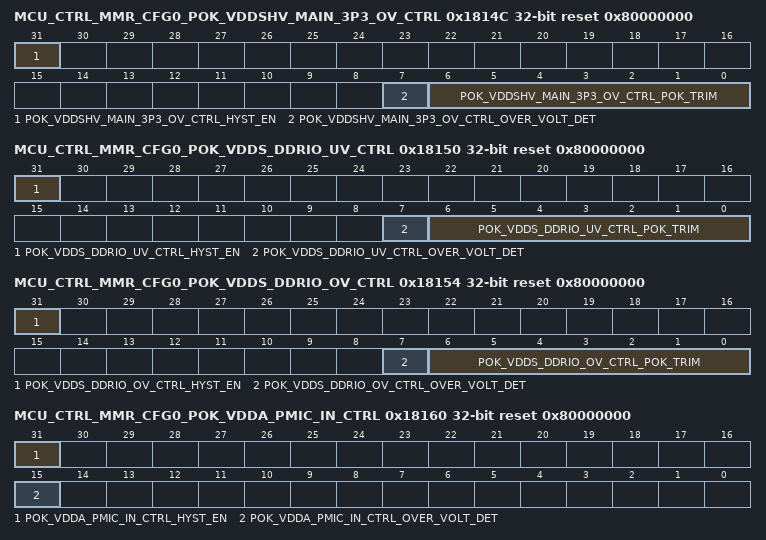
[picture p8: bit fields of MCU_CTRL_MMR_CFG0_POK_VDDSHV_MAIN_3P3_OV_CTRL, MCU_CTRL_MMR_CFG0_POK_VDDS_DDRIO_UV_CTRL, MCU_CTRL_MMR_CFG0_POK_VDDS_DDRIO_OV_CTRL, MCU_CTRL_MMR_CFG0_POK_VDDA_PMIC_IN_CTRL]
0x1814C MCU_CTRL_MMR_CFG0_POK_VDDSHV_MAIN_3P3_OV_CTRL reset 0x80000000
  [31] POK_VDDSHV_MAIN_3P3_OV_CTRL_HYST_EN — Activate POK hysteresis Reset Source: mod_por_rst_n
  [7] POK_VDDSHV_MAIN_3P3_OV_CTRL_OVER_VOLT_DET — Over / under voltage detection mode 0 - Under voltage detection 1 - Over voltage detection Reset Source: mod_por_rst_n
  [6:0] POK_VDDSHV_MAIN_3P3_OV_CTRL_POK_TRIM — POK Trim Bits Reset Source: mod_por_rst_n
0x18150 MCU_CTRL_MMR_CFG0_POK_VDDS_DDRIO_UV_CTRL reset 0x80000000
  [31] POK_VDDS_DDRIO_UV_CTRL_HYST_EN — Activate POK hysteresis Reset Source: mod_por_rst_n
  [7] POK_VDDS_DDRIO_UV_CTRL_OVER_VOLT_DET — Over / under voltage detection mode 0 - Under voltage detection 1 - Over voltage detection Reset Source: mod_por_rst_n
  [6:0] POK_VDDS_DDRIO_UV_CTRL_POK_TRIM — POK Trim Bits Reset Source: mod_por_rst_n
0x18154 MCU_CTRL_MMR_CFG0_POK_VDDS_DDRIO_OV_CTRL reset 0x80000000
  [31] POK_VDDS_DDRIO_OV_CTRL_HYST_EN — Activate POK hysteresis Reset Source: mod_por_rst_n
  [7] POK_VDDS_DDRIO_OV_CTRL_OVER_VOLT_DET — Over / under voltage detection mode 0 - Under voltage detection 1 - Over voltage detection Reset Source: mod_por_rst_n
  [6:0] POK_VDDS_DDRIO_OV_CTRL_POK_TRIM — POK Trim Bits Reset Source: mod_por_rst_n
0x18160 MCU_CTRL_MMR_CFG0_POK_VDDA_PMIC_IN_CTRL reset 0x80000000
  [31] POK_VDDA_PMIC_IN_CTRL_HYST_EN — Activate POK hysteresis Reset Source: mod_por_rst_n
  [15] POK_VDDA_PMIC_IN_CTRL_OVER_VOLT_DET — Over / under voltage detection mode 0 - Under voltage detection 1 - Over voltage detection Reset Source: mod_por_rst_n
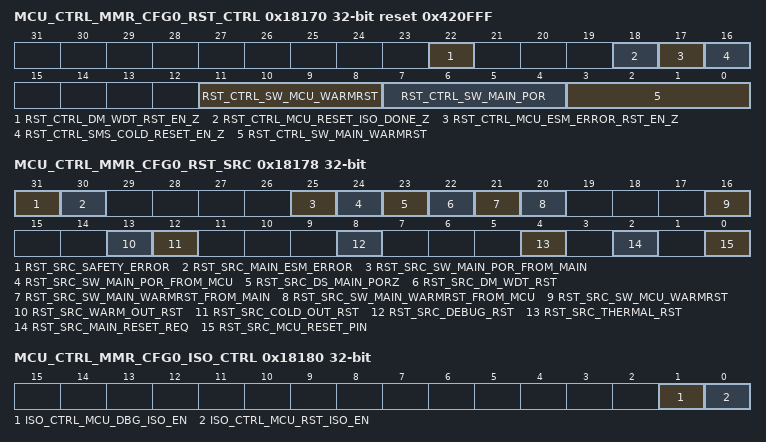
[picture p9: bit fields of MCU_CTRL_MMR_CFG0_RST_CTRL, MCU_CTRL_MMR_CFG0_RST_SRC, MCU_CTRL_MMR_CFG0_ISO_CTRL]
0x18170 MCU_CTRL_MMR_CFG0_RST_CTRL reset 0x420FFF
  [22] RST_CTRL_DM_WDT_RST_EN_Z — Deactivate Reset from DM WDT propogating to MCU domain: 0 - Activated 1 - Deactivated Reset Source: mcu_chip1_rst_n
  [18] RST_CTRL_MCU_RESET_ISO_DONE_Z — MCU can set this bit to block warm reset in the main domain which is useful when the MCU may be accessing main domain resources (peripherals, memory..). In this case, the MCU will be notified via an interrupt that there is an outstanding warm reset request for the main domain. Once notified, MCU needs to finish any outstanding operations in has with main domain resources and then clear this bit. After this bit is cleared, the main domain warm reset will unblocked and the warm reset sequence may continue. 0 - Reset of Main Domain is not Blocked by MCU Domain 1 - Reset of Main Domain is Blocked by MCU Domain Reset Source: mcu_chip1_rst_n
  [17] RST_CTRL_MCU_ESM_ERROR_RST_EN_Z — Deactivate Reset of MCU by ESM 0 - Activated 1 - Deactivated Reset Source: mcu_chip1_rst_n
  [16] RST_CTRL_SMS_COLD_RESET_EN_Z — Deactivate Reset of MCU by SMS 0 - Activated 1 - Deactivated Reset Source: mcu_chip1_rst_n
  [11:8] RST_CTRL_SW_MCU_WARMRST — This is a fault tolerant bitfield. Causes MCU Domain Warm Reset when set to 4'b0110, Bits will reset to 4'b1111 Reset Source: mcu_chip1_rst_n
  [7:4] RST_CTRL_SW_MAIN_POR — This is a fault tolerant bitfield. Causes MAIN Domain Power On Reset when set to 4'b0110, Bits will reset to 4'b1111 Reset Source: main_chip1_rst_n
  [3:0] RST_CTRL_SW_MAIN_WARMRST — This is a fault tolerant bitfield. Causes MAIN Domain Warm Reset when set to 4'b0110, Bits will reset to 4'b1111 Reset Source: main_chip1_rst_n
0x18174 MCU_CTRL_MMR_CFG0_RST_STAT ro
  [0] RST_STAT_MAIN_RESETSTATZ — Status of Main Domain Reset: 0 = Reset Asserted 1 = Reset Deasserted Reset Source: mcu_chip1_rst_n
0x18178 MCU_CTRL_MMR_CFG0_RST_SRC access not given
  [31] RST_SRC_SAFETY_ERROR — Reset Caused by MCU ESM Error Reset Source: mod_por_rst_n (access R/W1TC)
  [30] RST_SRC_MAIN_ESM_ERROR — Reset Caused by Main ESM Error Reset Source: mod_por_rst_n (access R/W1TC)
  [25] RST_SRC_SW_MAIN_POR_FROM_MAIN — Software Main Power On Reset From MAIN CTRL MMR Reset Source: mod_por_rst_n (access R/W1TC)
  [24] RST_SRC_SW_MAIN_POR_FROM_MCU — Software Main Power On Reset From MCU CTRL MMR Reset Source: mod_por_rst_n (access R/W1TC)
  [23] RST_SRC_DS_MAIN_PORZ — Reset of Main/Wkup Domains while in Deep Sleep, as a result of an MCU Warm Reset Reset Source: mod_por_rst_n (access R/W1TC)
  [22] RST_SRC_DM_WDT_RST — Watchdog Initiated Reset Reset Source: mod_por_rst_n (access R/W1TC)
  [21] RST_SRC_SW_MAIN_WARMRST_FROM_MAIN — Software Main Warm Reset from MAIN CTRL MMR Reset Source: mod_por_rst_n (access R/W1TC)
  [20] RST_SRC_SW_MAIN_WARMRST_FROM_MCU — Software Main Warm Reset From MCU CTRL MMR Reset Source: mod_por_rst_n (access R/W1TC)
  [16] RST_SRC_SW_MCU_WARMRST — Software Warm Reset Reset Source: mod_por_rst_n (access R/W1TC)
  [13] RST_SRC_WARM_OUT_RST — SMS Warm Reset Reset Source: mod_por_rst_n (access R/W1TC)
  [12] RST_SRC_COLD_OUT_RST — SMS Cold Reset Reset Source: mod_por_rst_n (access R/W1TC)
  [8] RST_SRC_DEBUG_RST — Debug Subsystem Initiated Reset Reset Source: mod_por_rst_n (access R/W1TC)
  [4] RST_SRC_THERMAL_RST — Thermal Reset Reset Source: mod_por_rst_n (access R/W1TC)
  [2] RST_SRC_MAIN_RESET_REQ — Main Reset Pin Reset Source: mod_por_rst_n (access R/W1TC)
  [0] RST_SRC_MCU_RESET_PIN — Rest Caused by MCU Reset Pin Reset Source: mod_por_rst_n (access R/W1TC)
0x1817C MCU_CTRL_MMR_CFG0_RST_MAGIC_WORD
  [31:0] RST_MAGIC_WORD_MCU_MAGIC_WORD — After a MCU_PORz reset this bit field resets to 0x00000000.While this bit field remains 0x00000000 any reset from the Main Domain also propagates through the MCU domain. If the application does not require reset isolation of the MCU domain, it shall leave this bit field with a value of 0x00000000.If the application does require reset isolation of the MCU domain afterthe initial boot, then the MCU R5FSS CPU must write a nonzero value to themagic word. The actual value is left to software and different values maybe used to convey information, but in order to isolate the MCU domainfrom any warm reset sources that triggers main_resetz, the value must be non-zero.If the value is nonzero and a Main domain warm reset that triggers main_resetz occurs in the main domain, the MCU R5FSS will not be reset. The Main domain bootloader must read this value to determine that the MCU R5FSS is already initialized, and has configured reset isolation. The Main domain bootloader then also skips any initialization steps involving bootstrapping the R5FSS (as it is is already running).Note that MCU_PORz reset is never blocked by a nonzero magic word. Reset Source: mcu_chip1_rst_n
0x18180 MCU_CTRL_MMR_CFG0_ISO_CTRL
  [1] ISO_CTRL_MCU_DBG_ISO_EN — Isolates the MCU domain from Debug Field values (others are reserved):undefined - undefinedundefined - undefined1'b0 - R5FSS is not debug isolated1'b1 - R5FSS is isolated from debug if RST_MAGIC_WORD is also nonzero Reset Source: mcu_chip1_rst_n
  [0] ISO_CTRL_MCU_RST_ISO_EN — Isolates the MCU domain from Warm Reset initiated by MainField values (others are reserved):undefined - undefinedundefined - undefined1'b0 - R5FSS is not reset isolated1'b1 - R5FSS is isolated from main warm reset if RST_MAGIC_WORD is also nonzero Reset Source: mcu_chip1_rst_n
